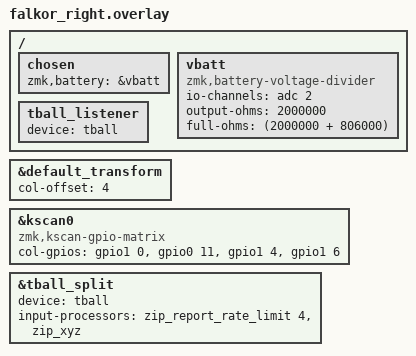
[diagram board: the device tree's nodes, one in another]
#include "falkor.dtsi"
#include "falkor_3610.dtsi"
#include "falkor_zplit.dtsi"
#include "falkor_nview.dtsi"
#include "falkor_esb_addr.dtsi"

&default_transform {
	col-offset = <4>;
};

&kscan0 {
	compatible = "zmk,kscan-gpio-matrix";
	
  col-gpios
      = <&gpio1 0 GPIO_ACTIVE_HIGH>
      , <&gpio0 11 GPIO_ACTIVE_HIGH>
      , <&gpio1 4 GPIO_ACTIVE_HIGH>
      , <&gpio1 6 GPIO_ACTIVE_HIGH>
      ;
};

/{
	chosen {
		zmk,battery = &vbatt;
	};
	vbatt: vbatt {
		compatible = "zmk,battery-voltage-divider";
		io-channels = <&adc 2>;
		output-ohms = <2000000>;
		full-ohms = <(2000000 + 806000)>;
	};
};

/ {
  tball_listener {
    status = "okay";
    device = <&tball>;
  };
};

#include <input/processors/report_rate_limit.dtsi>
#include <input/processors/xyz.dtsi>

&tball_split { device = <&tball>; input-processors = <&zip_report_rate_limit 4>, <&zip_xyz>; };
